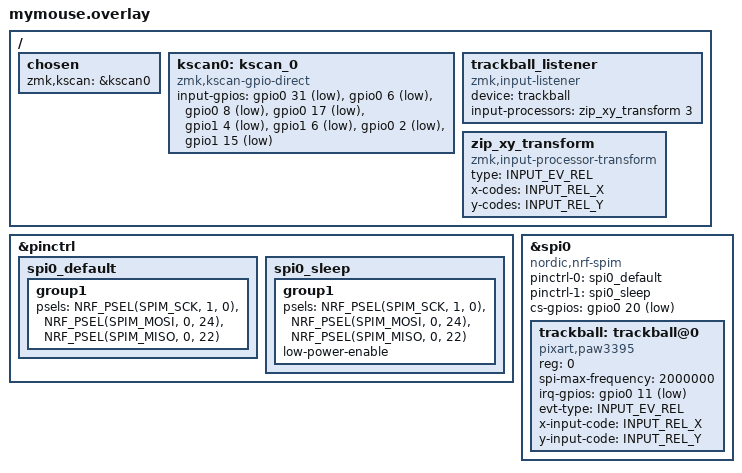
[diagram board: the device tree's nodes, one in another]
#include <zephyr/dt-bindings/input/input-event-codes.h>

/ {
    chosen {
        zmk,kscan = &kscan0;
    };

    kscan0: kscan_0 {
        compatible = "zmk,kscan-gpio-direct";
        input-gpios
            = <&gpio0 31 (GPIO_ACTIVE_LOW | GPIO_PULL_UP)>
            , <&gpio0 6  (GPIO_ACTIVE_LOW | GPIO_PULL_UP)>
            , <&gpio0 8  (GPIO_ACTIVE_LOW | GPIO_PULL_UP)>
            , <&gpio0 17 (GPIO_ACTIVE_LOW | GPIO_PULL_UP)>
            , <&gpio1 4  (GPIO_ACTIVE_LOW | GPIO_PULL_UP)>
            , <&gpio1 6  (GPIO_ACTIVE_LOW | GPIO_PULL_UP)>
            , <&gpio0 2  (GPIO_ACTIVE_LOW | GPIO_PULL_UP)>
            , <&gpio1 15 (GPIO_ACTIVE_LOW | GPIO_PULL_UP)>
            ;
    };

    trackball_listener {
        compatible = "zmk,input-listener";
        device = <&trackball>;
        input-processors = <&zip_xy_transform 3>;
    };

    zip_xy_transform: zip_xy_transform {
        compatible = "zmk,input-processor-transform";
        #input-processor-cells = <1>;
        type = <INPUT_EV_REL>;
        x-codes = <INPUT_REL_X>;
        y-codes = <INPUT_REL_Y>;
    };
};

&pinctrl {
    spi0_default: spi0_default {
        group1 {
            psels = <NRF_PSEL(SPIM_SCK,  1, 0)>,
                    <NRF_PSEL(SPIM_MOSI, 0, 24)>,
                    <NRF_PSEL(SPIM_MISO, 0, 22)>;
        };
    };
    spi0_sleep: spi0_sleep {
        group1 {
            psels = <NRF_PSEL(SPIM_SCK,  1, 0)>,
                    <NRF_PSEL(SPIM_MOSI, 0, 24)>,
                    <NRF_PSEL(SPIM_MISO, 0, 22)>;
            low-power-enable;
        };
    };
};

&spi0 {
    status = "okay";
    compatible = "nordic,nrf-spim";
    pinctrl-0 = <&spi0_default>;
    pinctrl-1 = <&spi0_sleep>;
    pinctrl-names = "default", "sleep";
    cs-gpios = <&gpio0 20 GPIO_ACTIVE_LOW>;

    trackball: trackball@0 {
        status = "okay";
        compatible = "pixart,paw3395";
        reg = <0>;
        spi-max-frequency = <2000000>;
        irq-gpios = <&gpio0 11 (GPIO_ACTIVE_LOW | GPIO_PULL_UP)>;
        evt-type = <INPUT_EV_REL>;
        x-input-code = <INPUT_REL_X>;
        y-input-code = <INPUT_REL_Y>;
    };
};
